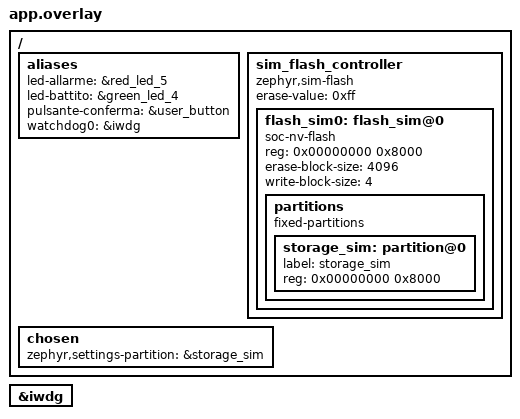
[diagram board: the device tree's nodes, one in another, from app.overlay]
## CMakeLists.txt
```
cmake_minimum_required(VERSION 3.20.0)
# Sensore di temperatura simulato (ADT7420 su bus I2C emulato, comando "sim temp"):
# vedi comune/ e CORSO.md, sezione 3. Va incluso prima di find_package.
include(${CMAKE_CURRENT_LIST_DIR}/../../comune/sensore_sim.cmake)
find_package(Zephyr REQUIRED HINTS $ENV{ZEPHYR_BASE})
project(nodo_monitoraggio)

# Tutti i file .c nella cartella src/ vengono compilati: per aggiungere un modulo
# (es. src/filtro.c) basta creare il file. CONFIGURE_DEPENDS fa si' che CMake se ne
# accorga da solo alla compilazione successiva.
file(GLOB app_sources CONFIGURE_DEPENDS src/*.c)
target_sources(app PRIVATE ${app_sources} ${SENSORE_SIM_SORGENTE})
```

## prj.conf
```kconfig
# Progetto finale: nodo di monitoraggio
# Configurazione di partenza. Ogni passo (modulo8/0N_*.md) dice quali opzioni aggiungere.
# Bus I2C, sensore (sensor API) e shell arrivano gia' da comune/sensore_sim.conf.

# LED e pulsante
CONFIG_GPIO=y

# Logging
CONFIG_LOG=y

# Nomi dei thread (utili in log, shell e thread analyzer)
CONFIG_THREAD_NAME=y
```

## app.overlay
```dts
/*
 * Hardware del nodo di monitoraggio (gia' pronto: e' configurazione).
 *
 * - alias con nomi "di progetto" per LED e pulsante: nel codice usa
 *   DT_ALIAS(led_allarme), DT_ALIAS(led_battito), DT_ALIAS(pulsante_conferma)
 *   (nel devicetree il trattino diventa underscore nelle macro).
 *     led-allarme       = LED rosso (PD14, led2)
 *     led-battito       = LED verde (PD12, led0)
 *     pulsante-conferma = pulsante utente blu (PA0, sw0)
 * - il sensore di temperatura (ADT7420, nodo "sensore") NON e' qui: lo aggiunge
 *   comune/sensore_sim.overlay, incluso dal CMakeLists.txt. Nel codice:
 *   DEVICE_DT_GET(DT_NODELABEL(sensore)) e la sensor API.
 * - watchdog indipendente IWDG attivato, con l'alias standard watchdog0.
 * - flash simulata in RAM per i settings (vedi modulo7/07_settings/app.overlay).
 */

/ {
	aliases {
		led-allarme = &red_led_5;
		led-battito = &green_led_4;
		pulsante-conferma = &user_button;
		watchdog0 = &iwdg;
	};

	sim_flash_controller: sim_flash_controller {
		compatible = "zephyr,sim-flash";
		#address-cells = <1>;
		#size-cells = <1>;
		erase-value = <0xff>;

		flash_sim0: flash_sim@0 {
			compatible = "soc-nv-flash";
			reg = <0x00000000 0x8000>;
			erase-block-size = <4096>;
			write-block-size = <4>;

			partitions {
				compatible = "fixed-partitions";
				#address-cells = <1>;
				#size-cells = <1>;

				storage_sim: partition@0 {
					label = "storage_sim";
					reg = <0x00000000 0x8000>;
				};
			};
		};
	};

	chosen {
		zephyr,settings-partition = &storage_sim;
	};
};

&iwdg {
	status = "okay";
};
```

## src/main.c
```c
/*
 * Progetto finale (Modulo 8) - Nodo di monitoraggio della temperatura
 *
 * Teoria: teoria/09_progettazione.md
 *
 * Questa applicazione cresce un passo alla volta. Le consegne sono in:
 *     modulo8/01_specifica.md       specifica e architettura (prima di scrivere codice!)
 *     modulo8/02_acquisizione.md    thread del sensore e coda delle misure
 *     modulo8/03_elaborazione.md    media mobile, soglia con isteresi, LED di allarme
 *     modulo8/04_pulsante.md        conferma dell'allarme con il pulsante, LED di battito
 *     modulo8/05_shell_config.md    comandi della shell, soglia salvata con settings
 *     modulo8/06_robustezza.md      watchdog, guasti del sensore, dimensionamento
 *     modulo8/07_test_relazione.md  test della logica e relazione finale
 *
 * Organizzazione dei file (la crei tu, passo dopo passo; ogni .c in src/ viene
 * compilato automaticamente, vedi CMakeLists.txt):
 *     main.c        avvio: prepara l'hardware, avvia i moduli, stampa NODO AVVIATO
 *     misura.h      struct misura (condivisa tra i moduli)
 *     sensore.c/h   thread di acquisizione (sensor API, sensore "sensore")
 *     filtro.c/h    media mobile (logica pura, testabile)
 *     allarme.c/h   macchina a stati dell'allarme con isteresi (logica pura, testabile)
 *     elabora.c/h   thread di elaborazione: coda -> filtro -> allarme -> uscite
 *     uscite.c/h    LED (allarme, battito)
 *     pulsante.c/h  pulsante a interrupt con debounce
 *     comandi.c     comandi della shell
 *     config.c/h    soglie e settings
 *     formato.c/h   stampa e lettura di numeri in centesimi (logica pura, testabile)
 *
 * Hardware (app.overlay): alias led_allarme (LED rosso, PD14), led_battito (LED verde,
 * PD12), pulsante_conferma (pulsante blu, PA0), watchdog0 (IWDG). Il sensore ADT7420
 * (nodo "sensore") arriva da comune/: la temperatura si cambia dalla console con
 * "sim temp <centesimi>" (es. sim temp 3500).
 *
 * Il comportamento richiesto e i formati di uscita (controllati dalle verifiche in
 * modulo8/verifiche/) sono descritti nei file dei passi.
 */

#include <zephyr/kernel.h>
#include <zephyr/sys/printk.h>

int main(void)
{
	/* Passo 2 e seguenti: inizializza i moduli qui. */

	printk("NODO AVVIATO\n");
	return 0;
}
```
